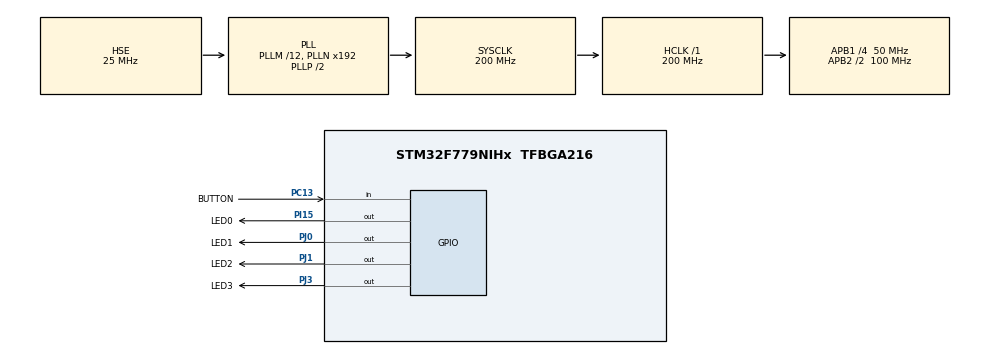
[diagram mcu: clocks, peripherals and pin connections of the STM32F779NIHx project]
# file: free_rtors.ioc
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FREERTOS.BinarySemaphores01=ButtonPressedSem,Static,ButtonPressedSemControlBlock
FREERTOS.Tasks01=defaultTask,24,128,StartDefaultTask,Default,NULL,Static,defaultTaskBuffer,defaultTaskControlBlock;Blink1Task,8,128,StartBlink1Task,Default,NULL,Static,Blink1TaskBuffer,Blink1TaskControlBlock;Blink2Task,8,128,StartBlink2Task,Default,NULL,Static,Blink2TaskBuffer,Blink2TaskControlBlock;ButtonTask,8,128,StartButtonTask,Default,NULL,Static,ButtonTaskBuffer,ButtonTaskControlBlock;LED3Task,8,128,StartLED3Task,Default,NULL,Static,LED3TaskBuffer,LED3TaskControlBlock
Mcu.Family=STM32F7
Mcu.Name=STM32F779NIHx
Mcu.Package=TFBGA216
NVIC.PriorityGroup=NVIC_PRIORITYGROUP_4
NVIC.TIM1_UP_TIM10_IRQn=true\:0\:0\:false\:false\:true\:false\:false\:true
NVIC.TimeBase=TIM1_UP_TIM10_IRQn
NVIC.TimeBaseIP=TIM1
PA13.Mode=Serial_Wire
PA13.Signal=SYS_JTMS-SWDIO
PA14.Mode=Serial_Wire
PA14.Signal=SYS_JTCK-SWCLK
PC13.GPIO_Label=BUTTON
PC13.GPIO_PuPd=GPIO_PULLDOWN
PC13.Signal=GPIO_Input
PH0/OSC_IN.Mode=HSE-External-Oscillator
PH0/OSC_IN.Signal=RCC_OSC_IN
PH1/OSC_OUT.Mode=HSE-External-Oscillator
PH1/OSC_OUT.Signal=RCC_OSC_OUT
PI15.GPIO_Label=LED0
PI15.PinState=GPIO_PIN_SET
PI15.Signal=GPIO_Output
PJ0.GPIO_Label=LED1
PJ0.PinState=GPIO_PIN_SET
PJ0.Signal=GPIO_Output
PJ1.GPIO_Label=LED2
PJ1.PinState=GPIO_PIN_SET
PJ1.Signal=GPIO_Output
PJ3.GPIO_Label=LED3
PJ3.PinState=GPIO_PIN_SET
PJ3.Signal=GPIO_Output
ProjectManager.HeapSize=0x200
ProjectManager.StackSize=0x400
ProjectManager.TargetToolchain=STM32CubeIDE
RCC.AHBFreq_Value=200000000
RCC.APB1CLKDivider=RCC_HCLK_DIV4
RCC.APB1Freq_Value=50000000
RCC.APB1TimFreq_Value=100000000
RCC.APB2CLKDivider=RCC_HCLK_DIV2
RCC.APB2Freq_Value=100000000
RCC.APB2TimFreq_Value=200000000
RCC.CortexFreq_Value=200000000
RCC.EnbaleCSS=true
RCC.HCLKFreq_Value=200000000
RCC.HSE_VALUE=25000000
RCC.HSI_VALUE=16000000
RCC.LSE_VALUE=32768
RCC.PLLM=12
RCC.PLLSourceVirtual=RCC_PLLSOURCE_HSE
RCC.SYSCLKFreq_VALUE=200000000
RCC.SYSCLKSource=RCC_SYSCLKSOURCE_PLLCLK
RCC.USBFreq_Value=200000000
RCC.VCOOutputFreq_Value=400000000
VP_FREERTOS_VS_CMSIS_V2.Mode=CMSIS_V2
VP_SYS_VS_tim1.Mode=TIM1
board=custom

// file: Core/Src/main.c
/* USER CODE BEGIN Header */
/**
  ******************************************************************************
  * @file           : main.c
  * @brief          : Main program body
  ******************************************************************************
  * @attention
  *
  * <h2><center>&copy; Copyright (c) 2019 STMicroelectronics.
  * All rights reserved.</center></h2>
  *
  * This software component is licensed by ST under BSD 3-Clause license,
  * the "License"; You may not use this file except in compliance with the
  * License. You may obtain a copy of the License at:
  *                        opensource.org/licenses/BSD-3-Clause
  *
  ******************************************************************************
  */
/* USER CODE END Header */

#include "main.h"
#include "cmsis_os.h"
#include "gpio.h"

void SystemClock_Config(void);
void MX_FREERTOS_Init(void);

int main(void)
{

  /* MCU Configuration--------------------------------------------------------*/

  /* Reset of all peripherals, Initializes the Flash interface and the Systick. */
  HAL_Init();

  /* Configure the system clock */
  SystemClock_Config();

  /* Initialize all configured peripherals */
  MX_GPIO_Init();

  /* Call init function for freertos objects (in freertos.c) */
  MX_FREERTOS_Init();

  /* Start scheduler */
  osKernelStart();

  /* We should never get here as control is now taken by the scheduler */

  /* Infinite loop */
  while (1)
  {

  }
}

void SystemClock_Config(void)
{
  RCC_OscInitTypeDef RCC_OscInitStruct = {0};
  RCC_ClkInitTypeDef RCC_ClkInitStruct = {0};

  /** Configure the main internal regulator output voltage
  */
  __HAL_RCC_PWR_CLK_ENABLE();
  __HAL_PWR_VOLTAGESCALING_CONFIG(PWR_REGULATOR_VOLTAGE_SCALE1);
  /** Initializes the CPU, AHB and APB busses clocks
  */
  RCC_OscInitStruct.OscillatorType = RCC_OSCILLATORTYPE_HSE;
  RCC_OscInitStruct.HSEState = RCC_HSE_ON;
  RCC_OscInitStruct.PLL.PLLState = RCC_PLL_ON;
  RCC_OscInitStruct.PLL.PLLSource = RCC_PLLSOURCE_HSE;
  RCC_OscInitStruct.PLL.PLLM = 12;
  RCC_OscInitStruct.PLL.PLLN = 192;
  RCC_OscInitStruct.PLL.PLLP = RCC_PLLP_DIV2;
  RCC_OscInitStruct.PLL.PLLQ = 2;
  if (HAL_RCC_OscConfig(&RCC_OscInitStruct) != HAL_OK)
  {
    Error_Handler();
  }
  /** Activate the Over-Drive mode
  */
  if (HAL_PWREx_EnableOverDrive() != HAL_OK)
  {
    Error_Handler();
  }
  /** Initializes the CPU, AHB and APB busses clocks
  */
  RCC_ClkInitStruct.ClockType = RCC_CLOCKTYPE_HCLK|RCC_CLOCKTYPE_SYSCLK
                              |RCC_CLOCKTYPE_PCLK1|RCC_CLOCKTYPE_PCLK2;
  RCC_ClkInitStruct.SYSCLKSource = RCC_SYSCLKSOURCE_PLLCLK;
  RCC_ClkInitStruct.AHBCLKDivider = RCC_SYSCLK_DIV1;
  RCC_ClkInitStruct.APB1CLKDivider = RCC_HCLK_DIV4;
  RCC_ClkInitStruct.APB2CLKDivider = RCC_HCLK_DIV2;

  if (HAL_RCC_ClockConfig(&RCC_ClkInitStruct, FLASH_LATENCY_6) != HAL_OK)
  {
    Error_Handler();
  }
  /** Enables the Clock Security System
  */
  HAL_RCC_EnableCSS();
}

void HAL_TIM_PeriodElapsedCallback(TIM_HandleTypeDef *htim)
{
  if (htim->Instance == TIM1) {
    HAL_IncTick();
  }
}

void Error_Handler(void)
{
}

/************************ (C) COPYRIGHT STMicroelectronics *****END OF FILE****/

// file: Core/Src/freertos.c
/* USER CODE BEGIN Header */
/**
  ******************************************************************************
  * File Name          : freertos.c
  * Description        : Code for freertos applications
  ******************************************************************************
  * @attention
  *
  * <h2><center>&copy; Copyright (c) 2019 STMicroelectronics.
  * All rights reserved.</center></h2>
  *
  * This software component is licensed by ST under Ultimate Liberty license
  * SLA0044, the "License"; You may not use this file except in compliance with
  * the License. You may obtain a copy of the License at:
  *                             www.st.com/SLA0044
  *
  ******************************************************************************
  */
/* USER CODE END Header */

#include "FreeRTOS.h"
#include "task.h"
#include "main.h"
#include "cmsis_os.h"

typedef StaticTask_t osStaticThreadDef_t;
typedef StaticSemaphore_t osStaticSemaphoreDef_t;
osThreadId_t defaultTaskHandle;
uint32_t defaultTaskBuffer[ 128 ];
osStaticThreadDef_t defaultTaskControlBlock;
osThreadId_t Blink1TaskHandle;
uint32_t Blink1TaskBuffer[ 128 ];
osStaticThreadDef_t Blink1TaskControlBlock;
osThreadId_t Blink2TaskHandle;
uint32_t Blink2TaskBuffer[ 128 ];
osStaticThreadDef_t Blink2TaskControlBlock;
osThreadId_t ButtonTaskHandle;
uint32_t ButtonTaskBuffer[ 128 ];
osStaticThreadDef_t ButtonTaskControlBlock;
osThreadId_t LED3TaskHandle;
uint32_t LED3TaskBuffer[ 128 ];
osStaticThreadDef_t LED3TaskControlBlock;
osSemaphoreId_t ButtonPressedSemHandle;
osStaticSemaphoreDef_t ButtonPressedSemControlBlock;

void StartDefaultTask(void *argument);
void StartBlink1Task(void *argument);
void StartBlink2Task(void *argument);
void StartButtonTask(void *argument);
void StartLED3Task(void *argument);

void MX_FREERTOS_Init(void); /* (MISRA C 2004 rule 8.1) */

void MX_FREERTOS_Init(void) {
osKernelInitialize();

  /* Create the semaphores(s) */
  /* definition and creation of ButtonPressedSem */
  const osSemaphoreAttr_t ButtonPressedSem_attributes = {
    .name = "ButtonPressedSem",
    .cb_mem = &ButtonPressedSemControlBlock,
    .cb_size = sizeof(ButtonPressedSemControlBlock),
  };
  ButtonPressedSemHandle = osSemaphoreNew(1, 1, &ButtonPressedSem_attributes);

  /* Create the thread(s) */
  /* definition and creation of defaultTask */
  const osThreadAttr_t defaultTask_attributes = {
    .name = "defaultTask",
    .stack_mem = &defaultTaskBuffer[0],
    .stack_size = sizeof(defaultTaskBuffer),
    .cb_mem = &defaultTaskControlBlock,
    .cb_size = sizeof(defaultTaskControlBlock),
    .priority = (osPriority_t) osPriorityNormal,
  };
  defaultTaskHandle = osThreadNew(StartDefaultTask, NULL, &defaultTask_attributes);

  /* definition and creation of Blink1Task */
  const osThreadAttr_t Blink1Task_attributes = {
    .name = "Blink1Task",
    .stack_mem = &Blink1TaskBuffer[0],
    .stack_size = sizeof(Blink1TaskBuffer),
    .cb_mem = &Blink1TaskControlBlock,
    .cb_size = sizeof(Blink1TaskControlBlock),
    .priority = (osPriority_t) osPriorityLow,
  };
  Blink1TaskHandle = osThreadNew(StartBlink1Task, NULL, &Blink1Task_attributes);

  /* definition and creation of Blink2Task */
  const osThreadAttr_t Blink2Task_attributes = {
    .name = "Blink2Task",
    .stack_mem = &Blink2TaskBuffer[0],
    .stack_size = sizeof(Blink2TaskBuffer),
    .cb_mem = &Blink2TaskControlBlock,
    .cb_size = sizeof(Blink2TaskControlBlock),
    .priority = (osPriority_t) osPriorityLow,
  };
  Blink2TaskHandle = osThreadNew(StartBlink2Task, NULL, &Blink2Task_attributes);

  /* definition and creation of ButtonTask */
  const osThreadAttr_t ButtonTask_attributes = {
    .name = "ButtonTask",
    .stack_mem = &ButtonTaskBuffer[0],
    .stack_size = sizeof(ButtonTaskBuffer),
    .cb_mem = &ButtonTaskControlBlock,
    .cb_size = sizeof(ButtonTaskControlBlock),
    .priority = (osPriority_t) osPriorityLow,
  };
  ButtonTaskHandle = osThreadNew(StartButtonTask, NULL, &ButtonTask_attributes);

  /* definition and creation of LED3Task */
  const osThreadAttr_t LED3Task_attributes = {
    .name = "LED3Task",
    .stack_mem = &LED3TaskBuffer[0],
    .stack_size = sizeof(LED3TaskBuffer),
    .cb_mem = &LED3TaskControlBlock,
    .cb_size = sizeof(LED3TaskControlBlock),
    .priority = (osPriority_t) osPriorityLow,
  };
  LED3TaskHandle = osThreadNew(StartLED3Task, NULL, &LED3Task_attributes);

}

void StartDefaultTask(void *argument)
{
  for(;;)
  {
    osDelay(1);
  }
}

void StartBlink1Task(void *argument)
{
  /* USER CODE BEGIN StartBlink1Task */
  /* Infinite loop */
  for(;;)
  {
	HAL_GPIO_TogglePin(LED0_GPIO_Port,LED0_Pin);
    osDelay(1000);
  }
  /* USER CODE END StartBlink1Task */
}

void StartBlink2Task(void *argument)
{
  /* USER CODE BEGIN StartBlink2Task */
  /* Infinite loop */
  for(;;)
  {
	HAL_GPIO_TogglePin(LED1_GPIO_Port,LED1_Pin);
    osDelay(2000);
  }
  /* USER CODE END StartBlink2Task */
}

void StartButtonTask(void *argument)
{
  /* USER CODE BEGIN StartButtonTask */
  /* Infinite loop */
  for(;;)
  {
	if (HAL_GPIO_ReadPin(BUTTON_GPIO_Port,BUTTON_Pin))
	{
		osSemaphoreRelease(ButtonPressedSemHandle);
	}
    osDelay(100);
  }
  /* USER CODE END StartButtonTask */
}

void StartLED3Task(void *argument)
{
  /* USER CODE BEGIN StartLED3Task */
  /* Infinite loop */
  for(;;)
  {
	  if (osSemaphoreAcquire(ButtonPressedSemHandle, osWaitForever) == osOK)
		 HAL_GPIO_TogglePin(LED3_GPIO_Port,LED3_Pin);
	  osThreadYield();
  }
  /* USER CODE END StartLED3Task */
}

/************************ (C) COPYRIGHT STMicroelectronics *****END OF FILE****/
